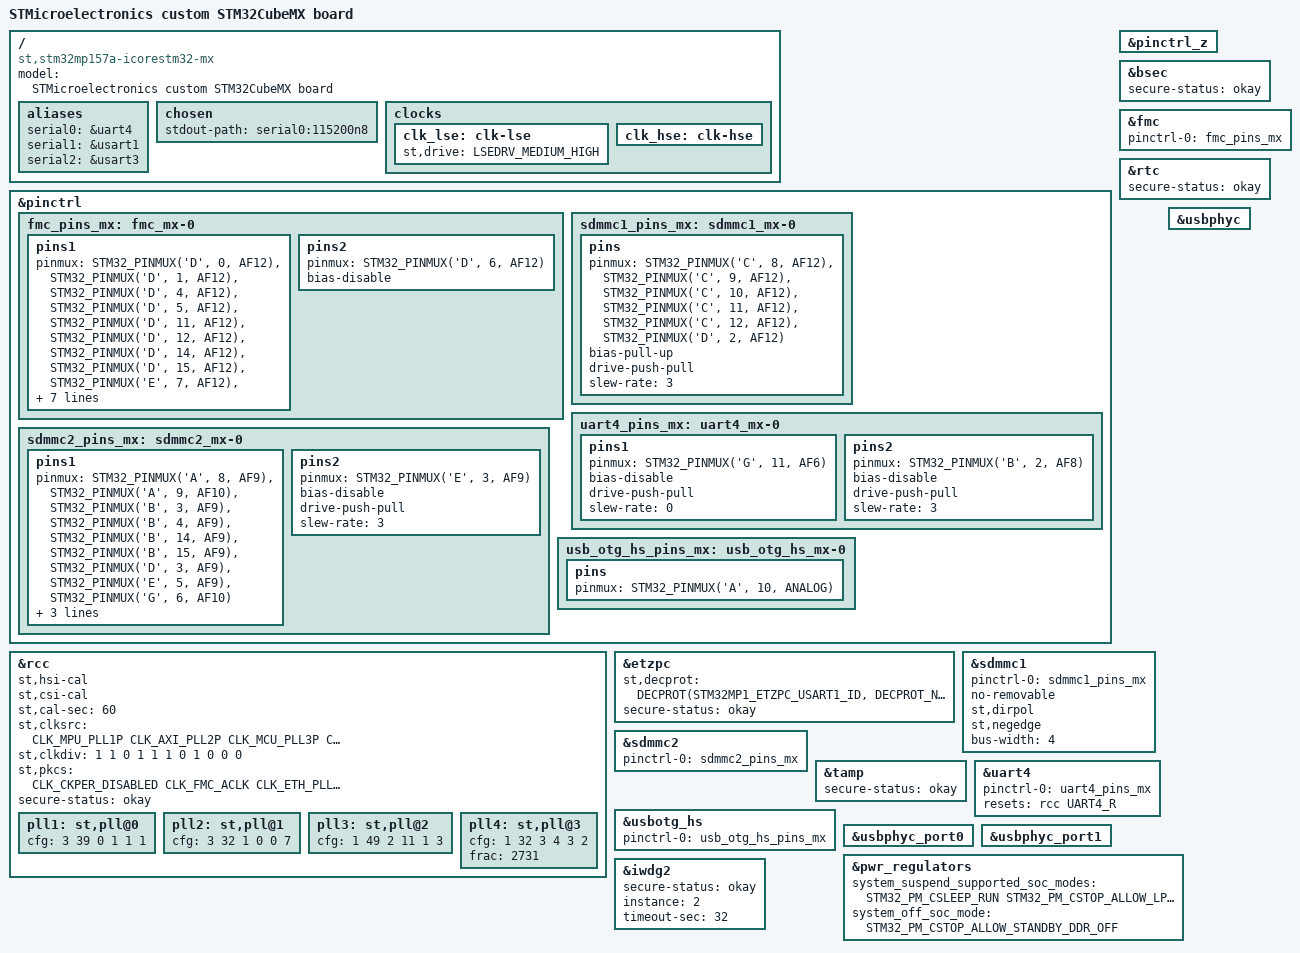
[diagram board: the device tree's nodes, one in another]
/* SPDX-License-Identifier: (GPL-2.0+ OR BSD-3-Clause) */
/*
 * Copyright (C) STMicroelectronics 2020 - All Rights Reserved
 * Author: STM32CubeMX code generation for STMicroelectronics.
 */

/* For more information on Device Tree configuration, please refer to
 * https://wiki.st.com/stm32mpu/wiki/Category:Device_tree_configuration
 */

/dts-v1/;
#include <dt-bindings/power/stm32mp1-power.h>
#include <dt-bindings/pinctrl/stm32-pinfunc.h>
#include <dt-bindings/clock/stm32mp1-clksrc.h>
#include <dt-bindings/soc/st,stm32-etzpc.h>
#include "stm32mp15-icore-mx.dtsi"

#include "stm32mp157.dtsi"
#include "stm32mp15xa.dtsi"
#include "stm32mp15xxaa-pinctrl.dtsi"
#include "stm32mp15-ddr.dtsi"

/* USER CODE BEGIN includes */
/* USER CODE END includes */

/ {
	model = "STMicroelectronics custom STM32CubeMX board";
	compatible = "st,stm32mp157a-icorestm32-mx", "st,stm32mp157";

	/* USER CODE BEGIN root */

	aliases {
		serial0 = &uart4;
		serial1 = &usart1;
		serial2 = &usart3;
	};

	chosen {
		stdout-path = "serial0:115200n8";
	};

	/* USER CODE END root */

clocks {
    /* USER CODE BEGIN clocks */
    /* USER CODE END clocks */

    clk_lse: clk-lse {
        /* USER CODE BEGIN clocks */
        /* USER CODE END clocks */
        st,drive=<LSEDRV_MEDIUM_HIGH>;
    };
    clk_hse: clk-hse {
        /* USER CODE BEGIN clocks */
        /* USER CODE END clocks */
    };
};

}; /*root*/

&pinctrl {
    fmc_pins_mx: fmc_mx-0 {
        pins1 {
            pinmux = <STM32_PINMUX('D', 0, AF12)>, /* FMC_D2 */
                     <STM32_PINMUX('D', 1, AF12)>, /* FMC_D3 */
                     <STM32_PINMUX('D', 4, AF12)>, /* FMC_NOE */
                     <STM32_PINMUX('D', 5, AF12)>, /* FMC_NWE */
                     <STM32_PINMUX('D', 11, AF12)>, /* FMC_CLE */
                     <STM32_PINMUX('D', 12, AF12)>, /* FMC_ALE */
                     <STM32_PINMUX('D', 14, AF12)>, /* FMC_D0 */
                     <STM32_PINMUX('D', 15, AF12)>, /* FMC_D1 */
                     <STM32_PINMUX('E', 7, AF12)>, /* FMC_D4 */
                     <STM32_PINMUX('E', 8, AF12)>, /* FMC_D5 */
                     <STM32_PINMUX('E', 9, AF12)>, /* FMC_D6 */
                     <STM32_PINMUX('E', 10, AF12)>, /* FMC_D7 */
                     <STM32_PINMUX('G', 9, AF12)>; /* FMC_NCE */
            bias-disable;
            drive-push-pull;
            slew-rate = <1>;
        };
        pins2 {
            pinmux = <STM32_PINMUX('D', 6, AF12)>; /* FMC_NWAIT */
            bias-disable;
        };
    };
    sdmmc1_pins_mx: sdmmc1_mx-0 {
        pins {
            pinmux = <STM32_PINMUX('C', 8, AF12)>, /* SDMMC1_D0 */
                     <STM32_PINMUX('C', 9, AF12)>, /* SDMMC1_D1 */
                     <STM32_PINMUX('C', 10, AF12)>, /* SDMMC1_D2 */
                     <STM32_PINMUX('C', 11, AF12)>, /* SDMMC1_D3 */
                     <STM32_PINMUX('C', 12, AF12)>, /* SDMMC1_CK */
                     <STM32_PINMUX('D', 2, AF12)>; /* SDMMC1_CMD */
            bias-pull-up;
            drive-push-pull;
            slew-rate = <3>;
        };
    };
    uart4_pins_mx: uart4_mx-0 {
        pins1 {
            pinmux = <STM32_PINMUX('G', 11, AF6)>; /* UART4_TX */
            bias-disable;
            drive-push-pull;
            slew-rate = <1>;
        };
        pins2 {
            pinmux = <STM32_PINMUX('C', 12, AF12)>; /*UART4_RX */
            bias-disable;
            drive-push-pull;
            slew-rate = <3>;
        };
    };
    sdmmc2_pins_mx: sdmmc2_mx-0 {
        pins1 {
            pinmux = <STM32_PINMUX('A', 8, AF9)>, /* SDMMC2_D4 */
                     <STM32_PINMUX('A', 9, AF10)>, /* SDMMC2_D5 */
                     <STM32_PINMUX('B', 3, AF9)>, /* SDMMC2_D2 */
                     <STM32_PINMUX('B', 4, AF9)>, /* SDMMC2_D3 */
                     <STM32_PINMUX('B', 14, AF9)>, /* SDMMC2_D0 */
                     <STM32_PINMUX('B', 15, AF9)>, /* SDMMC2_D1 */
                     <STM32_PINMUX('D', 3, AF9)>, /* SDMMC2_D7 */
                     <STM32_PINMUX('E', 5, AF9)>, /* SDMMC2_D6 */
                     <STM32_PINMUX('G', 6, AF10)>; /* SDMMC2_CMD */
            bias-disable;
            drive-push-pull;
            slew-rate = <1>;
        };
        pins2 {
            pinmux = <STM32_PINMUX('E', 3, AF9)>; /* SDMMC2_CK */
            bias-disable;
            drive-push-pull;
            slew-rate = <3>;
        };
    };
    uart4_pins_mx: uart4_mx-0 {
        pins1 {
            pinmux = <STM32_PINMUX('G', 11, AF6)>; /* UART4_TX */
            bias-disable;
            drive-push-pull;
            slew-rate = <0>;
        };
        pins2 {
            pinmux = <STM32_PINMUX('B', 2, AF8)>; /* UART4_RX */
            bias-disable;
        };
    };
    usb_otg_hs_pins_mx: usb_otg_hs_mx-0 {
        pins {
            pinmux = <STM32_PINMUX('A', 10, ANALOG)>; /* USB_OTG_HS_ID */
        };
    };
};

&pinctrl_z {
	/* USER CODE BEGIN pinctrl_z */
	/* USER CODE END pinctrl_z */
};

&rcc {
    st,hsi-cal;
    st,csi-cal;
    st,cal-sec = <60>;
    st,clksrc = <
        CLK_MPU_PLL1P
        CLK_AXI_PLL2P
        CLK_MCU_PLL3P
        CLK_PLL12_HSI
        CLK_PLL3_HSE
        CLK_PLL4_HSE
        CLK_RTC_LSE
        CLK_MCO1_DISABLED
        CLK_MCO2_DISABLED
    >;
    st,clkdiv = <
        1         /*MPU*/
        1         /*AXI*/
        0         /*MCU*/
        1         /*APB1*/
        1         /*APB2*/
        1         /*APB3*/
        0         /*APB4*/
        1         /*APB5*/
        0         /*RTC*/
        0         /*MCO1*/
        0         /*MCO2*/
    >;
    st,pkcs = <
        CLK_CKPER_DISABLED
        CLK_FMC_ACLK
        CLK_ETH_PLL3Q
        CLK_SDMMC12_HSI
        CLK_DSI_DSIPLL
        CLK_STGEN_HSI
        CLK_USBPHY_HSE
        CLK_SPI2S1_DISABLED
        CLK_SPI2S23_DISABLED
        CLK_SPI45_DISABLED
        CLK_SPI6_DISABLED
        CLK_I2C46_CSI
        CLK_SDMMC3_HCLK2
        CLK_USBO_USBPHY
        CLK_ADC_PLL4R
        CLK_CEC_DISABLED
        CLK_I2C12_PCLK1
        CLK_I2C35_DISABLED
        CLK_UART1_HSI
        CLK_UART24_HSE
        CLK_UART35_PCLK1
        CLK_UART6_DISABLED
        CLK_UART78_DISABLED
        CLK_SPDIF_DISABLED
        CLK_FDCAN_HSE
        CLK_SAI1_PLL4Q
        CLK_SAI2_PLL3Q
        CLK_SAI3_DISABLED
        CLK_SAI4_DISABLED
        CLK_LPTIM1_DISABLED
        CLK_LPTIM23_DISABLED
        CLK_LPTIM45_DISABLED
    >;
    pll1:st,pll@0 {
        cfg = < 3 39 0 1 1 1>;
    };
    pll2:st,pll@1 {
        cfg = < 3 32 1 0 0 7>;
    };
    pll3:st,pll@2 {
        cfg = < 1 49 2 11 1 3>;
    };
    pll4:st,pll@3 {
        cfg = < 1 32 3 4 3 2>;
        frac = < 2731 >;
    };
};


&bsec{
    status = "okay";
    secure-status = "okay";

    /* USER CODE BEGIN bsec */
    /* USER CODE END bsec */
};

&etzpc{
    st,decprot = <
    /*"Cortex-A7 non secure" context*/
	DECPROT(STM32MP1_ETZPC_USART1_ID, DECPROT_NS_RW, DECPROT_UNLOCK)
	DECPROT(STM32MP1_ETZPC_USART3_ID, DECPROT_NS_RW, DECPROT_UNLOCK)
	DECPROT(STM32MP1_ETZPC_UART4_ID, DECPROT_NS_RW, DECPROT_UNLOCK)
	DECPROT(STM32MP1_ETZPC_UART7_ID, DECPROT_NS_RW, DECPROT_UNLOCK)
    DECPROT(STM32MP1_ETZPC_UART8_ID, DECPROT_NS_RW, DECPROT_UNLOCK)
    DECPROT(STM32MP1_ETZPC_OTG_ID, DECPROT_NS_RW, DECPROT_UNLOCK)
    DECPROT(STM32MP1_ETZPC_SAI2_ID, DECPROT_NS_RW, DECPROT_UNLOCK)
    DECPROT(STM32MP1_ETZPC_ETH_ID, DECPROT_NS_RW, DECPROT_UNLOCK)
    DECPROT(STM32MP1_ETZPC_TT_FDCAN_ID, DECPROT_NS_RW, DECPROT_UNLOCK)
    DECPROT(STM32MP1_ETZPC_UART4_ID, DECPROT_NS_RW, DECPROT_UNLOCK)
    DECPROT(STM32MP1_ETZPC_I2C2_ID, DECPROT_NS_RW, DECPROT_UNLOCK)
    DECPROT(STM32MP1_ETZPC_I2C4_ID, DECPROT_NS_RW, DECPROT_UNLOCK)
    DECPROT(STM32MP1_ETZPC_I2C6_ID, DECPROT_NS_RW, DECPROT_UNLOCK)
    DECPROT(STM32MP1_ETZPC_FMC_ID, DECPROT_NS_RW, DECPROT_UNLOCK)
    DECPROT(STM32MP1_ETZPC_SDMMC3_ID, DECPROT_NS_RW, DECPROT_UNLOCK)

    /*Restriction: following IDs are not managed - please to use User-Section if needed:
     STM32MP1_ETZPC_DMA1_ID, STM32MP1_ETZPC_DMA2_ID, STM32MP1_ETZPC_DMAMUX_ID,
     STM32MP1_ETZPC_SRAMx_ID, STM32MP1_ETZPC_RETRAM_ID, STM32MP1_ETZPC_BKPSRAM_ID*/

    /* USER CODE BEGIN etzpc_decprot */
     /*STM32CubeMX generates a basic and standard configuration for ETZPC.
     Additional device configurations can be added here if needed.
     "etzpc" node could be also overloaded in "addons" User-Section.*/
    /* USER CODE END etzpc_decprot */
    >;
    secure-status = "okay";

    /* USER CODE BEGIN etzpc */
    /* USER CODE END etzpc */
};

&fmc{
    pinctrl-names = "default";
    pinctrl-0 = <&fmc_pins_mx>;
    status = "okay";

    /* USER CODE BEGIN fmc */
    /* USER CODE END fmc */
};

&rcc{
    status = "okay";
    secure-status = "okay";

    /* USER CODE BEGIN rcc */
    /* USER CODE END rcc */
};

&rtc{
    status = "okay";
    secure-status = "okay";

    /* USER CODE BEGIN rtc */
    /* USER CODE END rtc */
};

&sdmmc1{
    pinctrl-names = "default";
    pinctrl-0 = <&sdmmc1_pins_mx>;
    status = "okay";

    /* USER CODE BEGIN sdmmc1 */
    no-removable;
    st,dirpol;
    st,negedge;
    bus-width=<4>;
    /* USER CODE END sdmmc1 */
};

&sdmmc2{
    pinctrl-names = "default";
    pinctrl-0 = <&sdmmc2_pins_mx>;
    status = "okay";

    /* USER CODE BEGIN sdmmc2 */
    /* USER CODE END sdmmc2 */
};

&tamp{
	status = "okay";
	secure-status = "okay";

	/* USER CODE BEGIN tamp */
	/* USER CODE END tamp */
};

&uart4{
    pinctrl-names = "default";
    pinctrl-0 = <&uart4_pins_mx>;
    status = "okay";

    /* USER CODE BEGIN uart4 */
    resets = <&rcc UART4_R>;
    /* USER CODE END uart4 */
};

&usbotg_hs{
    pinctrl-names = "default";
    pinctrl-0 = <&usb_otg_hs_pins_mx>;
    status = "okay";

    /* USER CODE BEGIN usbotg_hs */
    /* USER CODE END usbotg_hs */
};

&usbphyc{
	status = "okay";
	/* USER CODE BEGIN usbphyc */
	/* USER CODE END usbphyc */
};

&usbphyc_port0{
	status = "okay";

	/* USER CODE BEGIN usbphyc_port0 */
	/* USER CODE END usbphyc_port0 */
};

&usbphyc_port1{
	status = "okay";

	/* USER CODE BEGIN usbphyc_port1 */
	/* USER CODE END usbphyc_port1 */
};

/* USER CODE BEGIN addons */
&pwr_regulators{
	system_suspend_supported_soc_modes = <
		STM32_PM_CSLEEP_RUN
		STM32_PM_CSTOP_ALLOW_LP_STOP
		STM32_PM_CSTOP_ALLOW_STANDBY_DDR_SR
	>;

	system_off_soc_mode = <STM32_PM_CSTOP_ALLOW_STANDBY_DDR_OFF>;

};

&iwdg2{
    status = "okay";
    secure-status = "okay";

    /* USER CODE BEGIN iwdg2 */
    instance = <2>;
    timeout-sec = <32>;
    /* USER CODE END iwdg2 */
};
/* USER CODE END addons */
